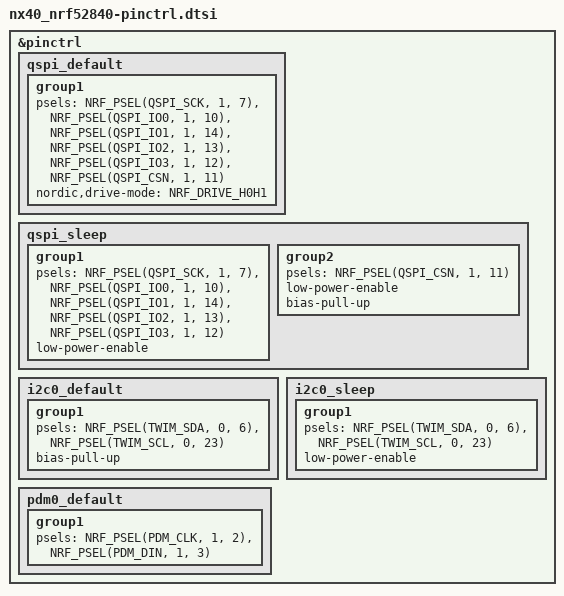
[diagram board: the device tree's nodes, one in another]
/*
 * Copyright (c) 2026 Korlinx
 *
 * SPDX-License-Identifier: Apache-2.0
 */

&pinctrl {
	qspi_default: qspi_default {
		group1 {
			psels = <NRF_PSEL(QSPI_SCK, 1, 7)>,
				<NRF_PSEL(QSPI_IO0, 1, 10)>,
				<NRF_PSEL(QSPI_IO1, 1, 14)>,
				<NRF_PSEL(QSPI_IO2, 1, 13)>,
				<NRF_PSEL(QSPI_IO3, 1, 12)>,
				<NRF_PSEL(QSPI_CSN, 1, 11)>;
			nordic,drive-mode = <NRF_DRIVE_H0H1>;
		};
	};

	qspi_sleep: qspi_sleep {
		group1 {
			psels = <NRF_PSEL(QSPI_SCK, 1, 7)>,
				<NRF_PSEL(QSPI_IO0, 1, 10)>,
				<NRF_PSEL(QSPI_IO1, 1, 14)>,
				<NRF_PSEL(QSPI_IO2, 1, 13)>,
				<NRF_PSEL(QSPI_IO3, 1, 12)>;
			low-power-enable;
		};
		group2 {
			psels = <NRF_PSEL(QSPI_CSN, 1, 11)>;
			low-power-enable;
			bias-pull-up;
		};
	};

	i2c0_default: i2c0_default {
		group1 {
			psels = <NRF_PSEL(TWIM_SDA, 0, 6)>,
				<NRF_PSEL(TWIM_SCL, 0, 23)>;
			bias-pull-up;
		};
	};

	i2c0_sleep: i2c0_sleep {
		group1 {
			psels = <NRF_PSEL(TWIM_SDA, 0, 6)>,
				<NRF_PSEL(TWIM_SCL, 0, 23)>;
			low-power-enable;
		};
	};

	pdm0_default: pdm0_default {
		group1 {
			psels = <NRF_PSEL(PDM_CLK, 1, 2)>,
				<NRF_PSEL(PDM_DIN, 1, 3)>;
		};
	};
};
